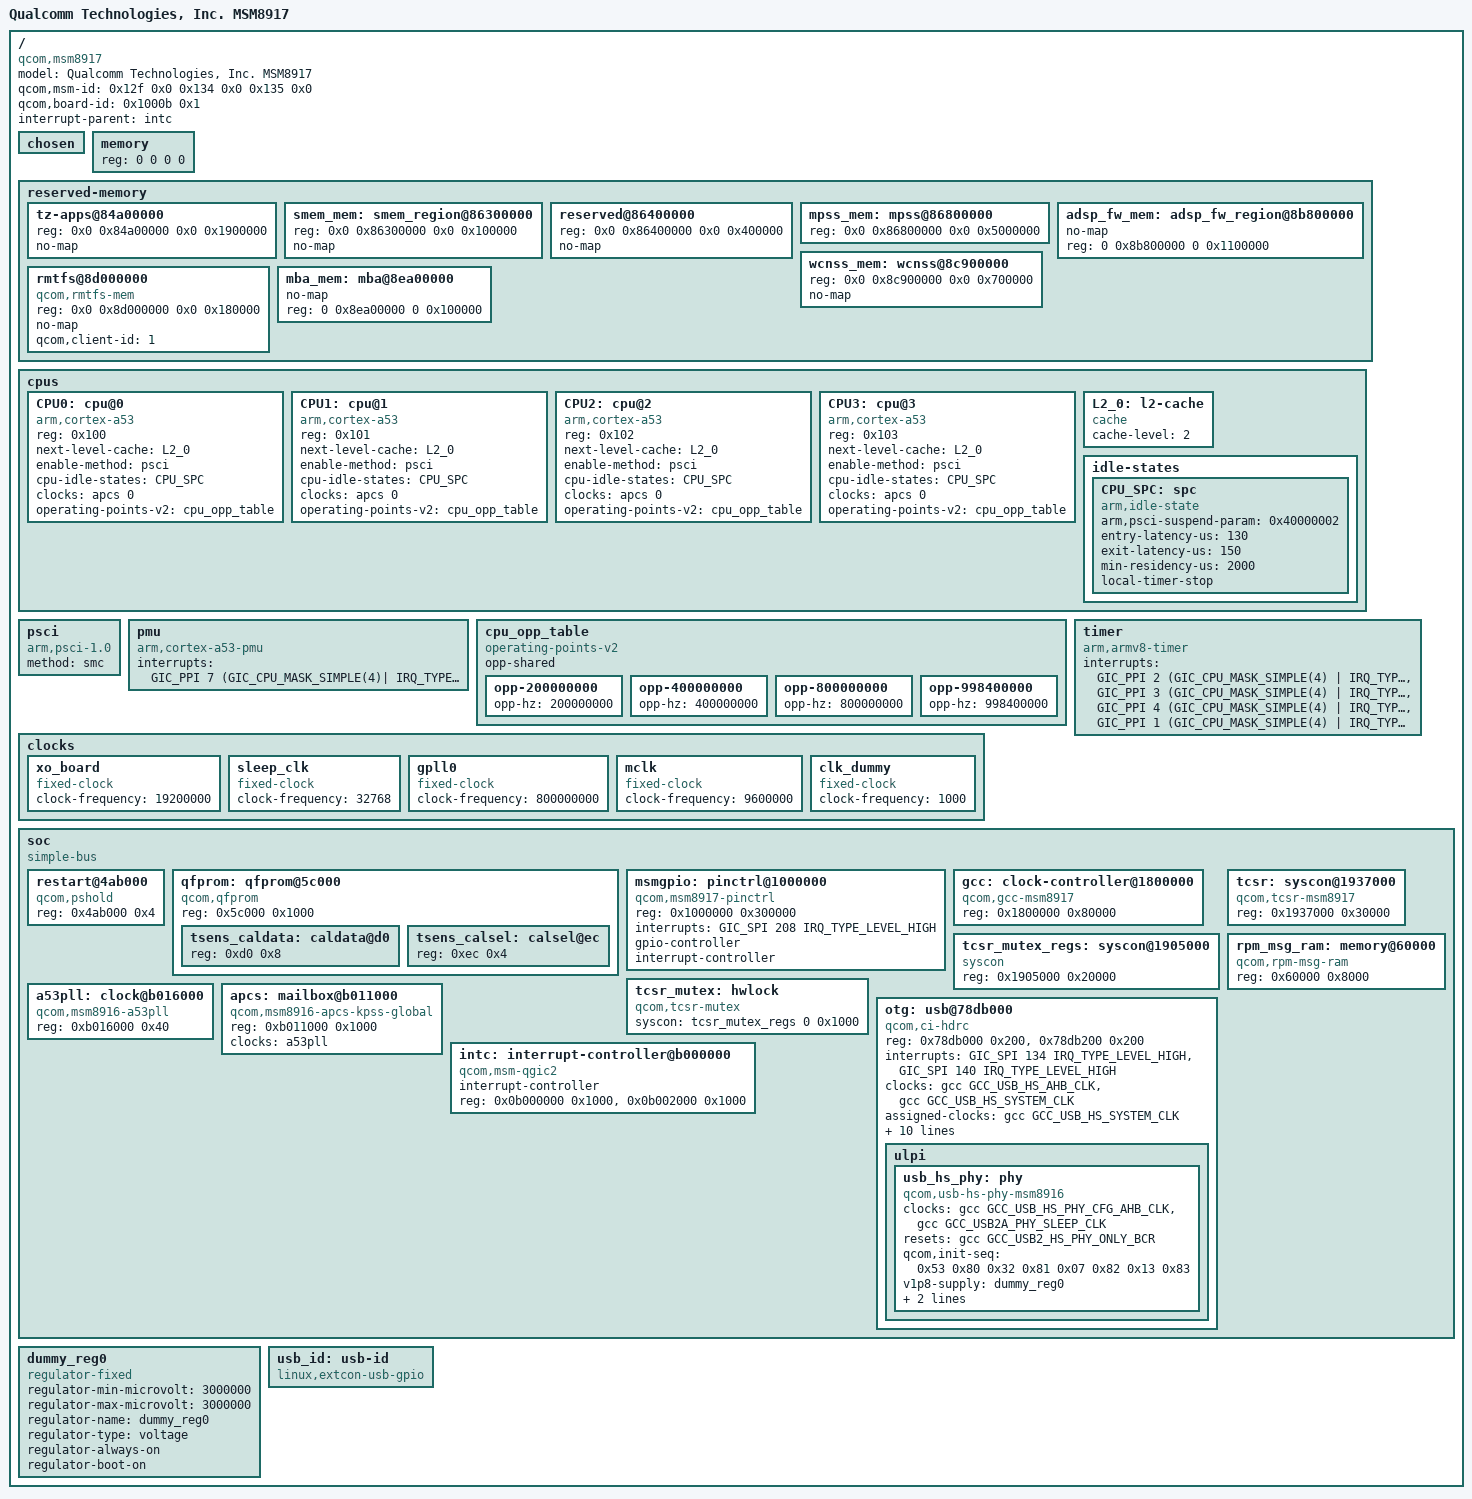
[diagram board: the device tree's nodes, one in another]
// SPDX-License-Identifier: GPL-2.0

#include <dt-bindings/interrupt-controller/arm-gic.h>
#include <dt-bindings/clock/qcom,gcc-msm8917.h>
#include <dt-bindings/reset/qcom,gcc-msm8917.h>
#include <dt-bindings/clock/qcom,rpmcc.h>
#include <dt-bindings/thermal/thermal.h>

#include <dt-bindings/soc/qcom,apr.h>
#include <dt-bindings/sound/qcom,q6afe.h>
#include <dt-bindings/sound/qcom,q6asm.h>

#include <dt-bindings/gpio/gpio.h>

/dts-v1/;

/ {
	model = "Qualcomm Technologies, Inc. MSM8917";
	compatible = "qcom,msm8917";

	// ids for bootloader
	qcom,msm-id = <0x12f 0x0 0x134 0x0 0x135 0x0>;
	qcom,board-id = <0x1000b 0x1>; // my device
	// qcom,board-id = <0x661 0x0>; // imirkin device

	interrupt-parent = <&intc>;

	#address-cells = <2>;
	#size-cells = <2>;

	chosen { };

	memory {
		device_type = "memory";
		/* We expect the bootloader to fill in the reg */
		reg = <0 0 0 0>;
	};

	reserved-memory {
		#address-cells = <2>;
		#size-cells = <2>;
		ranges;

		tz-apps@84a00000 {
			reg = <0x0 0x84a00000 0x0 0x1900000>;
			no-map;
		};

		smem_mem: smem_region@86300000 {
			reg = <0x0 0x86300000 0x0 0x100000>;
			no-map;
		};

		reserved@86400000 {
			reg = <0x0 0x86400000 0x0 0x400000>;
			no-map;
		};

		mpss_mem: mpss@86800000 {
			reg = <0x0 0x86800000 0x0 0x5000000>;
			//no-map;
		};

		adsp_fw_mem: adsp_fw_region@8b800000 {
			no-map;
			reg = <0 0x8b800000 0 0x1100000>;
		};

		wcnss_mem: wcnss@8c900000 {
			reg = <0x0 0x8c900000 0x0 0x700000>;
			no-map;
		};

		rmtfs@8d000000 {
			compatible = "qcom,rmtfs-mem";
			reg = <0x0 0x8d000000 0x0 0x180000>;
			no-map;

			qcom,client-id = <1>;
		};

		mba_mem: mba@8ea00000 {
			no-map;
			reg = <0 0x8ea00000 0 0x100000>;
		};
	};

	cpus {
		#address-cells = <1>;
		#size-cells = <0>;

		CPU0: cpu@0 {
			device_type = "cpu";
			compatible = "arm,cortex-a53", "arm,armv8";
			reg = <0x100>;
			next-level-cache = <&L2_0>;
			enable-method = "psci";
			cpu-idle-states = <&CPU_SPC>;
			clocks = <&apcs 0>;
			operating-points-v2 = <&cpu_opp_table>;
			#cooling-cells = <2>;
		};

		CPU1: cpu@1 {
			device_type = "cpu";
			compatible = "arm,cortex-a53", "arm,armv8";
			reg = <0x101>;
			next-level-cache = <&L2_0>;
			enable-method = "psci";
			cpu-idle-states = <&CPU_SPC>;
			clocks = <&apcs 0>;
			operating-points-v2 = <&cpu_opp_table>;
			#cooling-cells = <2>;
		};

		CPU2: cpu@2 {
			device_type = "cpu";
			compatible = "arm,cortex-a53", "arm,armv8";
			reg = <0x102>;
			next-level-cache = <&L2_0>;
			enable-method = "psci";
			cpu-idle-states = <&CPU_SPC>;
			clocks = <&apcs 0>;
			operating-points-v2 = <&cpu_opp_table>;
			#cooling-cells = <2>;
		};

		CPU3: cpu@3 {
			device_type = "cpu";
			compatible = "arm,cortex-a53", "arm,armv8";
			reg = <0x103>;
			next-level-cache = <&L2_0>;
			enable-method = "psci";
			cpu-idle-states = <&CPU_SPC>;
			clocks = <&apcs 0>;
			operating-points-v2 = <&cpu_opp_table>;
			#cooling-cells = <2>;
		};

		L2_0: l2-cache {
		      compatible = "cache";
		      cache-level = <2>;
		};

		idle-states {
			CPU_SPC: spc {
				compatible = "arm,idle-state";
				arm,psci-suspend-param = <0x40000002>;
				entry-latency-us = <130>;
				exit-latency-us = <150>;
				min-residency-us = <2000>;
				local-timer-stop;
			};
		};
	};

	psci {
		compatible = "arm,psci-1.0";
		method = "smc";
	};

	pmu {
		compatible = "arm,cortex-a53-pmu";
		interrupts = <GIC_PPI 7 (GIC_CPU_MASK_SIMPLE(4)| IRQ_TYPE_LEVEL_HIGH)>;
	};

	cpu_opp_table: cpu_opp_table {
		compatible = "operating-points-v2";
		opp-shared;

		opp-200000000 {
			opp-hz = /bits/ 64 <200000000>;
		};
		opp-400000000 {
			opp-hz = /bits/ 64 <400000000>;
		};
		opp-800000000 {
			opp-hz = /bits/ 64 <800000000>;
		};
		opp-998400000 {
			opp-hz = /bits/ 64 <998400000>;
		};
	};

	timer {
		compatible = "arm,armv8-timer";
		interrupts = <GIC_PPI 2 (GIC_CPU_MASK_SIMPLE(4) | IRQ_TYPE_LEVEL_LOW)>,
			     <GIC_PPI 3 (GIC_CPU_MASK_SIMPLE(4) | IRQ_TYPE_LEVEL_LOW)>,
			     <GIC_PPI 4 (GIC_CPU_MASK_SIMPLE(4) | IRQ_TYPE_LEVEL_LOW)>,
			     <GIC_PPI 1 (GIC_CPU_MASK_SIMPLE(4) | IRQ_TYPE_LEVEL_LOW)>;
	};

	clocks {
		xo_board: xo_board {
			compatible = "fixed-clock";
			#clock-cells = <0>;
			clock-frequency = <19200000>;
		};

		sleep_clk: sleep_clk {
			compatible = "fixed-clock";
			#clock-cells = <0>;
			clock-frequency = <32768>;
		};

		gpll0: gpll0 {
			compatible = "fixed-clock";
			#clock-cells = <0>;
			clock-frequency = <800000000>;
		};

		mclk: mclk {
			compatible = "fixed-clock";
			#clock-cells = <0>;
			clock-frequency = <9600000>;
		};

		clk_dummy: clk_dummy {
			compatible = "fixed-clock";
			#clock-cells = <0>;
			clock-frequency = <1000>;
		};
	};

	soc: soc {
		#address-cells = <1>;
		#size-cells = <1>;
		ranges = <0 0 0 0xffffffff>;
		compatible = "simple-bus";

		restart@4ab000 {
			compatible = "qcom,pshold";
			reg = <0x4ab000 0x4>;
		};

		qfprom: qfprom@5c000 {
			compatible = "qcom,qfprom";
			reg = <0x5c000 0x1000>;
			#address-cells = <1>;
			#size-cells = <1>;
			tsens_caldata: caldata@d0 {
				reg = <0xd0 0x8>;
			};
			tsens_calsel: calsel@ec {
				reg = <0xec 0x4>;
			};
		};

		msmgpio: pinctrl@1000000 {
			compatible = "qcom,msm8917-pinctrl";
			reg = <0x1000000 0x300000>;
			interrupts = <GIC_SPI 208 IRQ_TYPE_LEVEL_HIGH>;
			gpio-controller;
			#gpio-cells = <2>;
			interrupt-controller;
			#interrupt-cells = <2>;
		};

		gcc: clock-controller@1800000 {
			compatible = "qcom,gcc-msm8917";
			#clock-cells = <1>;
			#reset-cells = <1>;
			#power-domain-cells = <1>;
			reg = <0x1800000 0x80000>;
		};

		tcsr_mutex_regs: syscon@1905000 {
			compatible = "syscon";
			reg = <0x1905000 0x20000>;
		};

		tcsr: syscon@1937000 {
			compatible = "qcom,tcsr-msm8917", "syscon";
			reg = <0x1937000 0x30000>;
		};

		tcsr_mutex: hwlock {
			compatible = "qcom,tcsr-mutex";
			syscon = <&tcsr_mutex_regs 0 0x1000>;
			#hwlock-cells = <1>;
		};

		rpm_msg_ram: memory@60000 {
			compatible = "qcom,rpm-msg-ram";
			reg = <0x60000 0x8000>;
		};

		a53pll: clock@b016000 {
			compatible = "qcom,msm8916-a53pll";
			reg = <0xb016000 0x40>;
			#clock-cells = <0>;
		};

		apcs: mailbox@b011000 {
			compatible = "qcom,msm8916-apcs-kpss-global", "syscon";
			reg = <0xb011000 0x1000>;
			#mbox-cells = <1>;
			clocks = <&a53pll>;
			#clock-cells = <0>;
		};

#if 1
		otg: usb@78db000 {
			compatible = "qcom,ci-hdrc";
			reg = <0x78db000 0x200>,
			      <0x78db200 0x200>;
			interrupts = <GIC_SPI 134 IRQ_TYPE_LEVEL_HIGH>,
				     <GIC_SPI 140 IRQ_TYPE_LEVEL_HIGH>;
			clocks = <&gcc GCC_USB_HS_AHB_CLK>,
				 <&gcc GCC_USB_HS_SYSTEM_CLK>;
			clock-names = "iface", "core";
			assigned-clocks = <&gcc GCC_USB_HS_SYSTEM_CLK>;
			assigned-clock-rates = <80000000>;
			resets = <&gcc GCC_USB_HS_BCR>;
			reset-names = "core";
			phy_type = "ulpi";
			dr_mode = "otg";
			ahb-burst-config = <0>;
			phy-names = "usb-phy";
			phys = <&usb_hs_phy>;
			status = "ok";
			#reset-cells = <1>;

			adp-disable;
			hnp-disable;
			srp-disable;

			extcon = <&usb_id>, <&usb_id>;

			ulpi {
				usb_hs_phy: phy {
					compatible = "qcom,usb-hs-phy-msm8916",
						     "qcom,usb-hs-phy";
					#phy-cells = <0>;
					clocks = <&gcc GCC_USB_HS_PHY_CFG_AHB_CLK>, <&gcc GCC_USB2A_PHY_SLEEP_CLK>;
					clock-names = "ref", "sleep";
					resets = <&gcc GCC_USB2_HS_PHY_ONLY_BCR>;
					reset-names = "por";
					qcom,init-seq = /bits/ 8 <0x53 0x80 0x32 0x81 0x07 0x82 0x13 0x83>;

					v1p8-supply = <&dummy_reg0>;
					v3p3-supply = <&dummy_reg0>;
					extcon = <&usb_id>;
					// vdd_dig l2 ?
				};
			};
		};
#endif

		intc: interrupt-controller@b000000 {
			compatible = "qcom,msm-qgic2";
			interrupt-controller;
			#interrupt-cells = <3>;
			reg = <0x0b000000 0x1000>, <0x0b002000 0x1000>;
		};

	};

	// to be removed
	dummy_reg0: dummy_reg0 {
		compatible = "regulator-fixed";
		regulator-min-microvolt = <3000000>;
		regulator-max-microvolt = <3000000>;
		regulator-name = "dummy_reg0";
		regulator-type = "voltage";
		regulator-always-on;
		regulator-boot-on;
	};

	usb_id: usb-id {
		compatible = "linux,extcon-usb-gpio";
		// vbus-gpio = <&msmgpio 91 GPIO_ACTIVE_HIGH>;
	};
};
